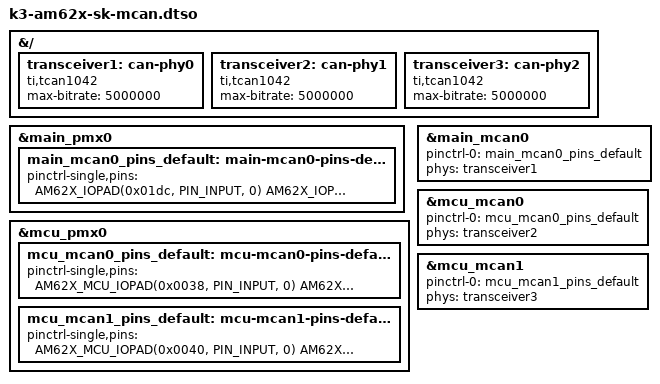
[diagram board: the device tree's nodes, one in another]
// SPDX-License-Identifier: GPL-2.0
/**
 * DT overlay to enable MCAN on AM625-SK, AM62A-SK, AM62 LP-SK
 *
 * Copyright (C) 2023 Texas Instruments Incorporated - https://www.ti.com/
 */

/dts-v1/;
/plugin/;

#include "k3-pinctrl.h"

&{/} {
	transceiver1: can-phy0 {
		compatible = "ti,tcan1042";
		#phy-cells = <0>;
		max-bitrate = <5000000>;
	};

	transceiver2: can-phy1 {
		compatible = "ti,tcan1042";
		#phy-cells = <0>;
		max-bitrate = <5000000>;
	};

	transceiver3: can-phy2 {
		compatible = "ti,tcan1042";
		#phy-cells = <0>;
		max-bitrate = <5000000>;
	};
};

&main_pmx0 {
	main_mcan0_pins_default: main-mcan0-pins-default {
		pinctrl-single,pins = <
			AM62X_IOPAD(0x01dc, PIN_INPUT, 0) /* (E15) MCAN0_RX */
			AM62X_IOPAD(0x01d8, PIN_OUTPUT, 0) /* (C15) MCAN0_TX */
		>;
	};
};

&mcu_pmx0 {
	mcu_mcan0_pins_default: mcu-mcan0-pins-default {
		pinctrl-single,pins = <
			AM62X_MCU_IOPAD(0x0038, PIN_INPUT, 0) /* (B3) MCU_MCAN0_RX */
			AM62X_MCU_IOPAD(0x0034, PIN_OUTPUT, 0) /* (D6) MCU_MCAN0_TX */
		>;
	};

	mcu_mcan1_pins_default: mcu-mcan1-pins-default {
		pinctrl-single,pins = <
			AM62X_MCU_IOPAD(0x0040, PIN_INPUT, 0) /* (D4) MCU_MCAN1_RX */
			AM62X_MCU_IOPAD(0x003c, PIN_OUTPUT, 0) /* (E5) MCU_MCAN1_TX */
		>;
	};
};

&main_mcan0 {
	pinctrl-names = "default";
	pinctrl-0 = <&main_mcan0_pins_default>;
	phys = <&transceiver1>;
	status = "okay";
};

&mcu_mcan0 {
	pinctrl-names = "default";
	pinctrl-0 = <&mcu_mcan0_pins_default>;
	phys = <&transceiver2>;
	status = "okay";
};

&mcu_mcan1 {
	pinctrl-names = "default";
	pinctrl-0 = <&mcu_mcan1_pins_default>;
	phys = <&transceiver3>;
	status = "okay";
};
